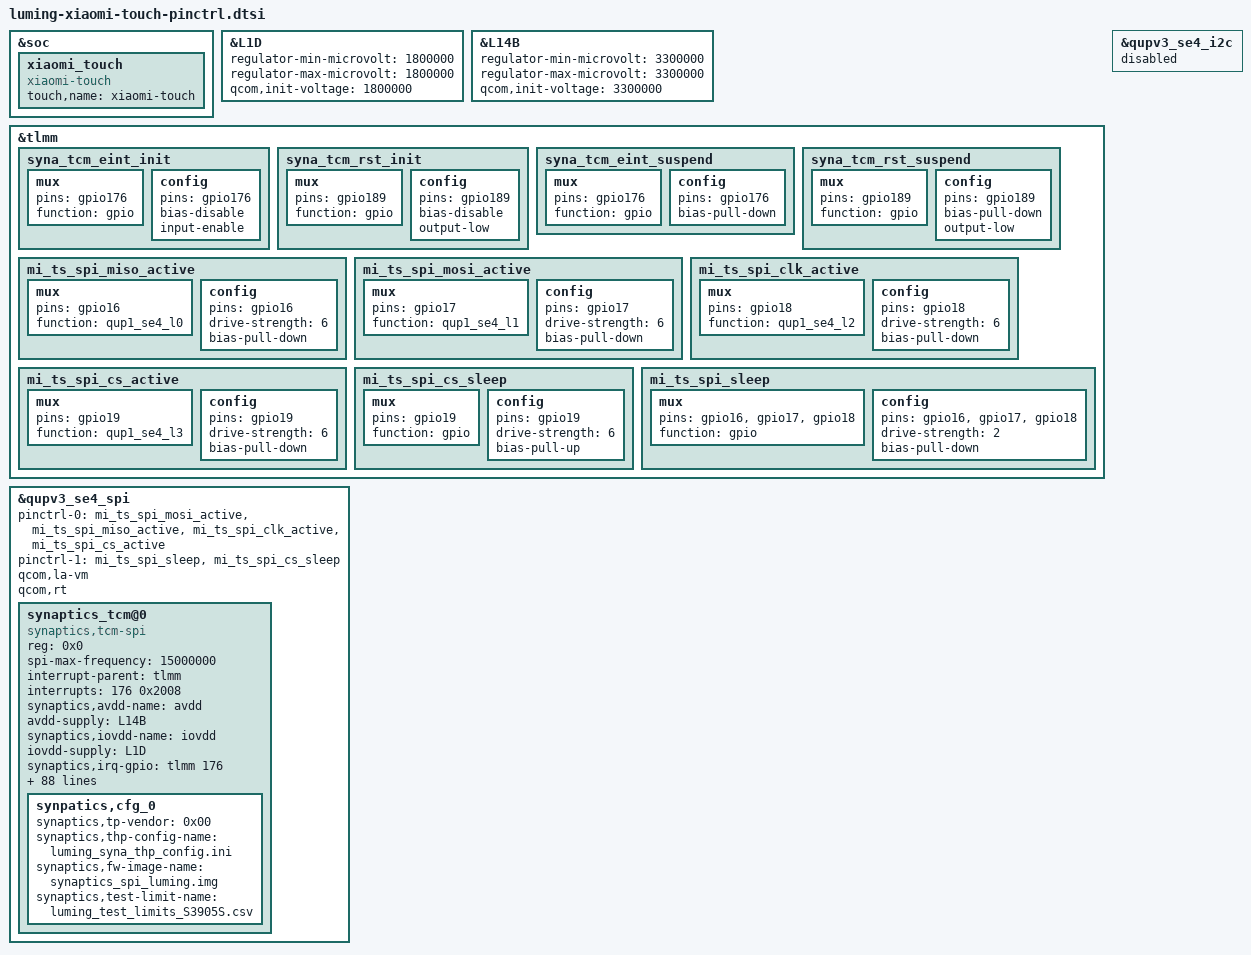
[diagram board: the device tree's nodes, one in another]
/*
  this file is for attribution only of dada
  And public attribution of xiaomi platforms(like O9)
*/

&soc {
	xiaomi_touch {
		compatible = "xiaomi-touch";
		status = "ok";
		touch,name = "xiaomi-touch";
	};
};

&L1D {
	regulator-min-microvolt = <1800000>;
	regulator-max-microvolt = <1800000>;
	qcom,init-voltage = <1800000>;
};

&L14B {
	regulator-min-microvolt = <3300000>;
	regulator-max-microvolt = <3300000>;
	qcom,init-voltage = <3300000>;
	/*ldob14/L14B is using need open*/
	status = "ok";
};

&tlmm {
	syna_tcm_eint_init: syna_tcm_eint_init {
		mux {
			/* GPIO 176 Interrupt */
			pins = "gpio176";
			function = "gpio";
		};

		config {
			pins = "gpio176";
			bias-disable;
			input-enable;
		};
	};

	syna_tcm_rst_init: syna_tcm_rst_init {
		mux {
			/* GPIO 189 Interrupt */
			pins = "gpio189";
			function = "gpio";
		};

		config {
			pins = "gpio189";
			bias-disable;
			output-low;
		};
	};

	syna_tcm_eint_suspend: syna_tcm_eint_suspend {
		mux {
			/* GPIO 176 Interrupt */
			pins = "gpio176";
			function = "gpio";
		};

		config {
			pins = "gpio176";
			bias-pull-down;
		};
	};

	syna_tcm_rst_suspend: syna_tcm_rst_suspend {
		mux {
			/* GPIO 189 Interrupt */
			pins = "gpio189";
			function = "gpio";
		};

		config {
			pins = "gpio189";
			bias-pull-down;
			output-low;
		};
	};

	mi_ts_spi_miso_active: mi_ts_spi_miso_active {
		mux {
			pins = "gpio16";
			function = "qup1_se4_l0";
		};
		config {
			pins = "gpio16";
			drive-strength = <6>;
			bias-pull-down;
		};
	};

	mi_ts_spi_mosi_active: mi_ts_spi_mosi_active {
		mux {
			pins = "gpio17";
			function = "qup1_se4_l1";
		};
		config {
			pins = "gpio17";
			drive-strength = <6>;
			bias-pull-down;
		};
	};

	mi_ts_spi_clk_active: mi_ts_spi_clk_active {
		mux {
			pins = "gpio18";
			function = "qup1_se4_l2";
		};
		config {
			pins = "gpio18";
			drive-strength = <6>;
			bias-pull-down;
		};
	};

	mi_ts_spi_cs_active: mi_ts_spi_cs_active {
		mux {
			pins = "gpio19";
			function = "qup1_se4_l3";
		};
		config {
			pins = "gpio19";
			drive-strength = <6>;
			bias-pull-down;
		};
	};


	mi_ts_spi_cs_sleep: mi_ts_spi_cs_sleep {
		mux {
			pins = "gpio19";
			function = "gpio";
		};
		config {
			pins = "gpio19";
			drive-strength = <6>;
			bias-pull-up;
		};
	};

	mi_ts_spi_sleep: mi_ts_spi_sleep {
		mux {
			pins = "gpio16", "gpio17",
				"gpio18";
			function = "gpio";
		};
		config {
			pins = "gpio16", "gpio17",
				"gpio18";
			drive-strength = <2>;
			bias-pull-down;
		};
	};
};

&qupv3_se4_i2c {
    status = "disabled";
};

&qupv3_se4_spi {
	status = "ok";
	pinctrl-0 = <&mi_ts_spi_mosi_active>, <&mi_ts_spi_miso_active>,
				<&mi_ts_spi_clk_active>, <&mi_ts_spi_cs_active>;
	pinctrl-1 = <&mi_ts_spi_sleep>, <&mi_ts_spi_cs_sleep>;
	qcom,la-vm;
	qcom,rt;
	synaptics_tcm@0 {
		compatible = "synaptics,tcm-spi";
		reg = <0x0>;
		spi-max-frequency = <15000000>;
		interrupt-parent = <&tlmm>;
		interrupts = <176 0x2008>;
		synaptics,avdd-name = "avdd";
		avdd-supply = <&L14B>;
		synaptics,iovdd-name = "iovdd";
		iovdd-supply = <&L1D>;
		/*synaptics,bus-reg-name = "vdd";*/
		/*synaptics,pwr-reg-name = "avdd";*/
		synaptics,irq-gpio = <&tlmm 176 0x2008>;
		synaptics,reset-gpio = <&tlmm 189 0x00>;
		synaptics,irq-on-state = <0>;
		synaptics,spi-mode = <0>;
		synaptics,byte-delay-us = <0>;
		synaptics,block-delay-us = <0>;
		synaptics,power-delay-ms = <50>;
		synaptics,reset-active-ms = <10>;
		synaptics,reset-delay-ms = <200>;
		synaptics,ubl-max-freq = <15000000>;
		synaptics,ubl-byte-delay-us = <20>;
		synaptics,fod-lx=<503>;
		synaptics,fod-ly=<2369>;
		synaptics,fod-x-size=<218>;
		synaptics,fod-y-size=<218>;
		synaptics,max-x = <1236>;
		synaptics,max-y = <2750>;
		synaptics,rx-num = <17>;
		synaptics,tx-num = <38>;
		synaptics,special-rx-num = <17>;
		synaptics,special-tx-num = <38>;
		synaptics,frame-data-page-size = <1>;
		synaptics,frame-data-buf-size = <10>;
		synaptics,raw-data-page-size = <5>;
		synaptics,raw-data-buf-size = <5>;
		pinctrl-names = "pmx_ts_active","pmx_ts_suspend";
		pinctrl-0 = <&syna_tcm_eint_init &syna_tcm_rst_init>;
		pinctrl-1 = <&syna_tcm_eint_suspend &syna_tcm_rst_suspend>;
		synaptics,super-resolution-factor = <100>;
		synaptics,panel-display-resolution = <1236 2750>;  /* X  Y*/
		mi_tp,game-mode-array =
				<1 0 0 0 0>;  /* MAX MIN DEF SET GET	*/
		mi_tp,active-mode-array =
				<1 0 0 0 0>;  /* MAX MIN DEF SET GET	*/
		mi_tp,tolerance-array =
				<4 0 2 2 2>;  /* MAX MIN DEF SET GET	*/
		mi_tp,up-threshold-array =
				<4 0 3 3 3>;  /* MAX MIN DEF SET GET	*/
		mi_tp,aim-sensitivity-array =
				<4 0 2 2 2>;  /* MAX MIN DEF SET GET	*/
		mi_tp,tap-stability-array =
				<4 0 2 2 2>;  /* MAX MIN DEF SET GET	*/
		mi_tp,edge-filter-array =
				<3 0 2 2 2>;  /* MAX MIN DEF SET GET	*/
		mi_tp,panel-orien-array =
				<3 0 0 0 0>;  /* MAX MIN DEF SET GET	*/
		mi_tp,report-rate-array =
				<3 0 0 0 0>;  /* MAX MIN DEF SET GET	*/
		mi_tp,expert-mode-array =
				<3 1 1 1 1>;  /* MAX MIN DEF SET GET	*/
		mi_tp,cornerfilter-area-step-array = <0 100 170 250>; /* step 0 to step 3 */
		mi_tp,cornerzone-filter-hor1-array =
                /* B0:Type, B1:pos, B2:x0, B3:y0, B4:x1, B5:y1, B6:reserved, B7: reserved */
                        <0 0 0 0 170 170 0 0>,
                        <0 1 0 0 0 0 0 0>,
                        <0 2 0 2579 170 2749 0 0>,
                        <0 3 0 0 0 0 0 0>;
		mi_tp,cornerzone-filter-hor2-array =
                /* B0:Type, B1:pos, B2:x0, B3:y0, B4:x1, B5:y1, B6:reserved, B7: reserved */
                        <0 0 0 0 0 0 0 0>,
                        <0 1 1065 0 1235 170 0 0>,
                        <0 2 0 0 0 0 0 0>,
                        <0 3 1065 2579 1235 2749 0 0>;
		mi_tp,cornerzone-filter-ver-array =
                /* B0:Type, B1:pos, B2:x0, B3:y0, B4:x1, B5:y1, B6:reserved, B7: reserved */
                        <0 0 0 0 0 0 0 0>,
                        <0 1 0 0 0 0 0 0>,
                        <0 2 0 2449 150 2749 0 0>,
                        <0 3 1085 2449 1235 2749 0 0>;
		mi_tp,deadzone-filter-hor-array =
                /* B0:Type, B1:pos, B2:x0, B3:y0, B4:x1, B5:y1, B6:reserved, B7: reserved */
                        <2 0 0 0 1235 2 0 0>,
                        <2 1 0 2747 1235 2749 0 0>,
                        <2 2 0 0 2 2749 0 0>,
                        <2 3 1233 0 1235 2479 0 0>;
		mi_tp,deadzone-filter-ver-array =
                /* B0:Type, B1:pos, B2:x0, B3:y0, B4:x1, B5:y1, B6:reserved, B7: reserved */
                        <2 0 0 0 1235 2 0 0>,
                        <2 1 0 2747 1235 2749 0 0>,
                        <2 2 0 0 2 2749 0 0>,
                        <2 3 1233 0 1235 2749 0 0>;
		mi_tp,edgezone-filter-hor-array =
                /* B0:Type, B1:pos, B2:x0, B3:y0, B4:x1, B5:y1, B6:reserved, B7: reserved */
                        <1 0 0 0 1235 30 0 0>,
                        <1 1 0 2719 1235 2749 0 0>,
                        <1 2 0 0 30 2749 0 0>,
                        <1 3 1205 0 1235 2749 0 0>;
		mi_tp,edgezone-filter-ver-array =
                /* B0:Type, B1:pos, B2:x0, B3:y0, B4:x1, B5:y1, B6:reserved, B7: reserved */
                        <1 0 0 0 1235 20 0 0>,
                        <1 1 0 2729 1235 2749 0 0>,
                        <1 2 0 0 40 2749 0 0>,
                        <1 3 1195 0 1235 2749 0 0>;
		syna,qts_en;
		syna,touch-type = "primary";
		qts,trusted-touch-mode = "vm_mode";
		qts,touch-environment = "tvm";
		qts,trusted-touch-type = "primary";
		qts,trusted-touch-spi-irq = <652>;
		qts,trusted-touch-io-bases = <0xa88000>;
		qts,trusted-touch-io-sizes = <0x1000>;
		qts,trusted-touch-vm-gpio-list = <&tlmm 16 0 &tlmm 17 0 &tlmm 18 0
                                          &tlmm 19 0 &tlmm 189 0 &tlmm 176 0x2008>;
		synaptics,config-array-size = <1>;
		synaptics,default-thp-config-name = "luming_syna_thp_config.ini";
		synaptics,default-fw-image-name = "synaptics_spi_luming.img";
		synaptics,default-test-limit-name = "luming_test_limits_S3905S.csv";
		synpatics,cfg_0 {
			synaptics,tp-vendor = <0x00>;
			synaptics,thp-config-name = "luming_syna_thp_config.ini";
			synaptics,fw-image-name = "synaptics_spi_luming.img";
			synaptics,test-limit-name = "luming_test_limits_S3905S.csv";
		};
	};
};
